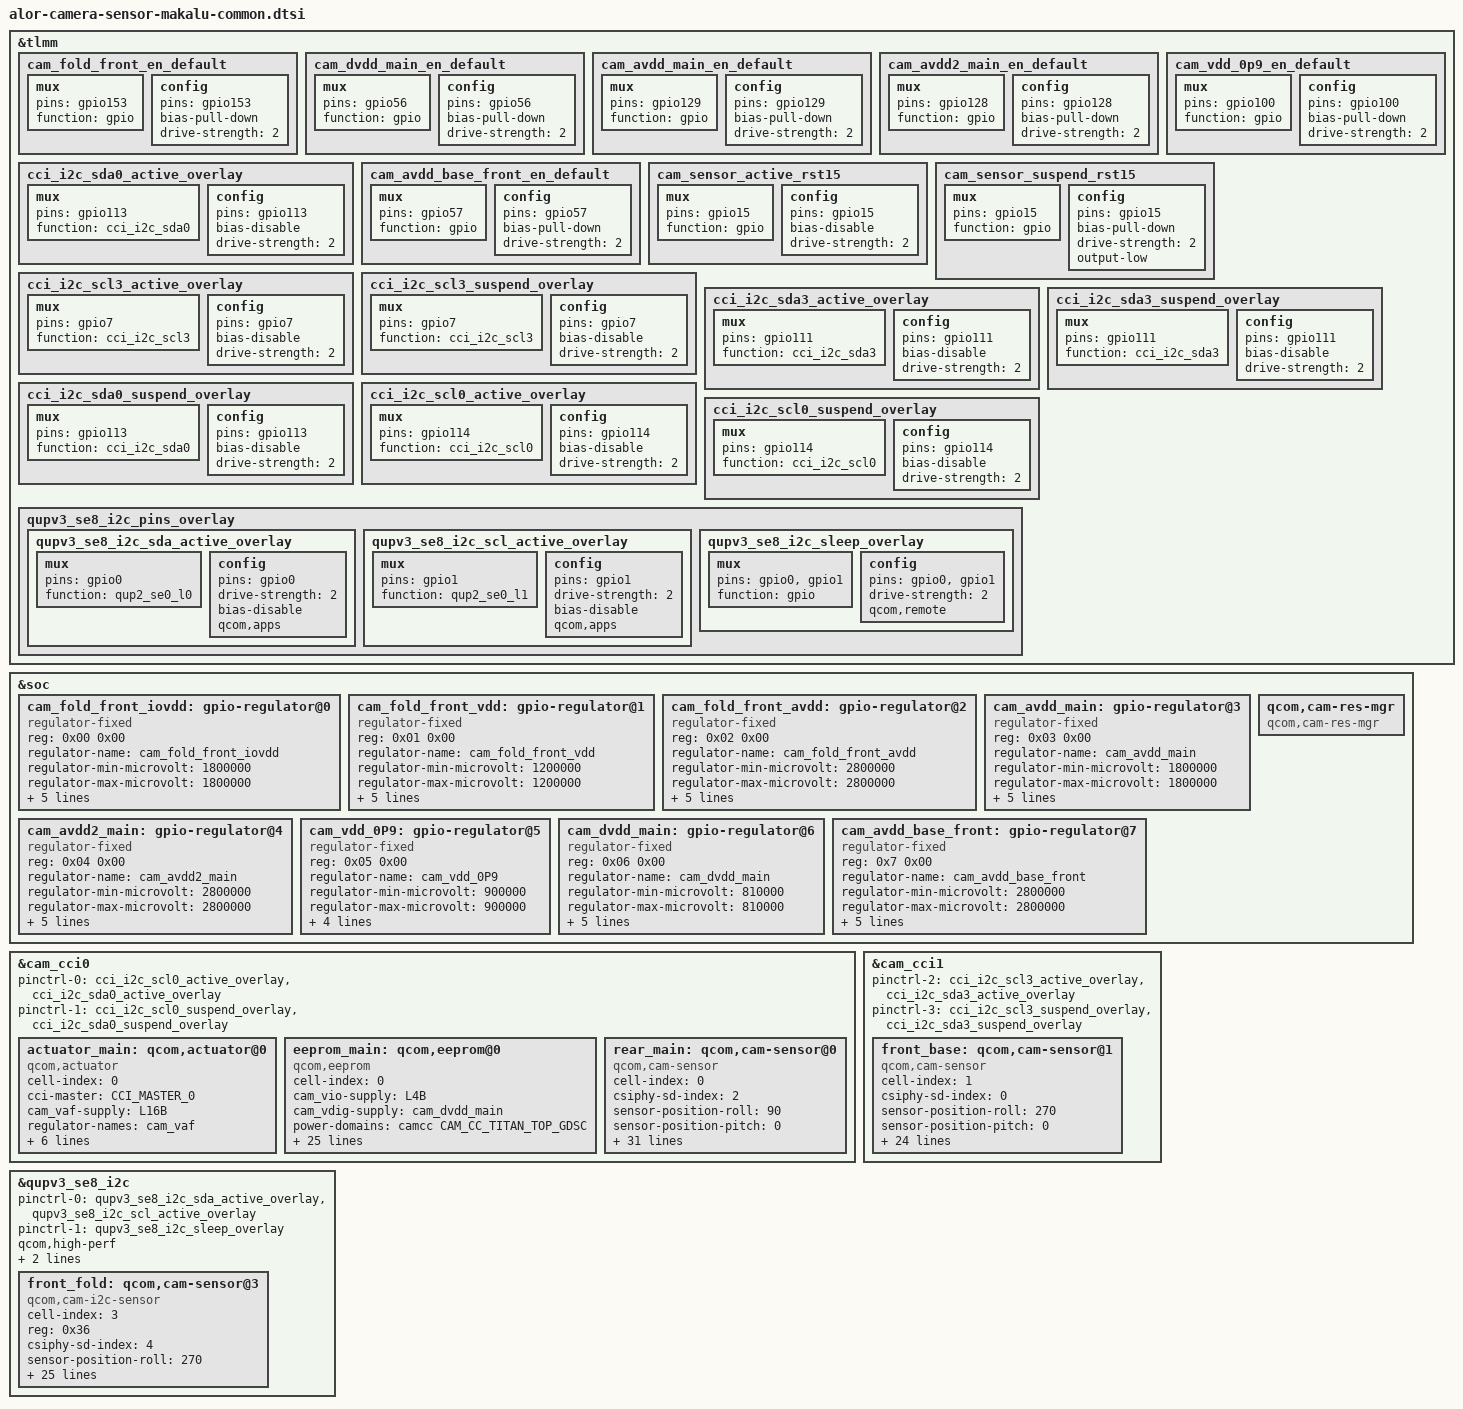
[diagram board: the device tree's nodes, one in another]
// SPDX-License-Identifier: BSD-3-Clause
/*
 * Copyright (c) 2024 Qualcomm Innovation Center, Inc. All rights reserved.
 */

#include <dt-bindings/msm-camera.h>

&tlmm {
	cam_fold_front_en_default: cam_fold_front_en_default {
		mux {
			pins = "gpio153";
			function = "gpio";
		};

		config {
			pins = "gpio153";
			bias-pull-down; /* PULL DOWN */
			drive-strength = <2>; /* 2 MA */
		};
	};

	cam_dvdd_main_en_default: cam_dvdd_main_en_default {
		mux {
			pins = "gpio56";
			function = "gpio";
		};

		config {
			pins = "gpio56";
			bias-pull-down; /* PULL DOWN */
			drive-strength = <2>; /* 2 MA */
		};
	};

	cam_avdd_main_en_default: cam_avdd_main_en_default {
		mux {
			pins = "gpio129";
			function = "gpio";
		};

		config {
			pins = "gpio129";
			bias-pull-down; /* PULL DOWN */
			drive-strength = <2>; /* 2 MA */
		};
	};

	cam_avdd2_main_en_default: cam_avdd2_main_en_default {
		mux {
			pins = "gpio128";
			function = "gpio";
		};

		config {
			pins = "gpio128";
			bias-pull-down; /* PULL DOWN */
			drive-strength = <2>; /* 2 MA */
		};
	};

	cam_vdd_0p9_en_default: cam_vdd_0p9_en_default {
		mux {
			pins = "gpio100";
			function = "gpio";
		};

		config {
			pins = "gpio100";
			bias-pull-down; /* PULL DOWN */
			drive-strength = <2>; /* 2 MA */
		};
	};

	cci_i2c_sda0_active_overlay: cci_i2c_sda0_active_overlay {
		/* SDA0 */
		mux {
			pins = "gpio113";
			function = "cci_i2c_sda0";
		};

		config {
			pins = "gpio113";
			bias-disable;
			drive-strength = <2>; /* 2 MA */
		};
	};

	cam_avdd_base_front_en_default: cam_avdd_base_front_en_default {
		mux {
			pins = "gpio57";
			function = "gpio";
		};

		config {
			pins = "gpio57";
			bias-pull-down; /* PULL DOWN */
			drive-strength = <2>; /* 2 MA */
		};
	};

	cam_sensor_active_rst15: cam_sensor_active_rst15 {
		mux {
			pins = "gpio15";
			function = "gpio";
		};

		config {
			pins = "gpio15";
			bias-disable; /* No PULL */
			drive-strength = <2>; /* 2 MA */
		};
	};

	cam_sensor_suspend_rst15: cam_sensor_suspend_rst15 {
		mux {
			pins = "gpio15";
			function = "gpio";
		};

		config {
			pins = "gpio15";
			bias-pull-down; /* PULL DOWN */
			drive-strength = <2>; /* 2 MA */
			output-low;
		};
	};

	cci_i2c_scl3_active_overlay: cci_i2c_scl3_active_overlay {
		/* SCL3 */
		mux {
			pins = "gpio7";
			function = "cci_i2c_scl3";
		};

		config {
			pins = "gpio7";
			bias-disable;
			drive-strength = <2>; /* 2 MA */
		};
	};

	cci_i2c_scl3_suspend_overlay: cci_i2c_scl3_suspend_overlay {
		/* SCL3 */
		mux {
			pins = "gpio7";
			function = "cci_i2c_scl3";
		};

		config {
			pins = "gpio7";
			bias-disable;
			drive-strength = <2>; /* 2 MA */
		};
	};

	cci_i2c_sda3_active_overlay: cci_i2c_sda3_active_overlay {
		/* SDA3 */
		mux {
			pins = "gpio111";
			function = "cci_i2c_sda3";
		};

		config {
			pins = "gpio111";
			bias-disable;
			drive-strength = <2>; /* 2 MA */
		};
	};

	cci_i2c_sda3_suspend_overlay: cci_i2c_sda3_suspend_overlay {
		/* SDA3 */
		mux {
			pins = "gpio111";
			function = "cci_i2c_sda3";
		};

		config {
			pins = "gpio111";
			bias-disable;
			drive-strength = <2>; /* 2 MA */
		};
	};

	cci_i2c_sda0_suspend_overlay: cci_i2c_sda0_suspend_overlay {
		/* SDA0 */
		mux {
			pins = "gpio113";
			function = "cci_i2c_sda0";
		};

		config {
			pins = "gpio113";
			bias-disable;
			drive-strength = <2>; /* 2 MA */
		};
	};

	cci_i2c_scl0_active_overlay: cci_i2c_scl0_active_overlay {
		/* SCL0 */
		mux {
			pins = "gpio114";
			function = "cci_i2c_scl0";
		};

		config {
			pins = "gpio114";
			bias-disable;
			drive-strength = <2>; /* 2 MA */
		};
	};

	cci_i2c_scl0_suspend_overlay: cci_i2c_scl0_suspend_overlay {
		/* SCL0 */
		mux {
			pins = "gpio114";
			function = "cci_i2c_scl0";
		};

		config {
			pins = "gpio114";
			bias-disable;
			drive-strength = <2>; /* 2 MA */
		};
	};

	qupv3_se8_i2c_pins_overlay: qupv3_se8_i2c_pins_overlay {
		qupv3_se8_i2c_sda_active_overlay: qupv3_se8_i2c_sda_active_overlay {
			mux {
				pins = "gpio0";
				function = "qup2_se0_l0";
			};

			config {
				pins = "gpio0";
				drive-strength = <2>;
				bias-disable;
				qcom,apps;
			};
		};

		qupv3_se8_i2c_scl_active_overlay: qupv3_se8_i2c_scl_active_overlay {
			mux {
				pins = "gpio1";
				function = "qup2_se0_l1";
			};

			config {
				pins = "gpio1";
				drive-strength = <2>;
				bias-disable;
				qcom,apps;
			};
		};

		qupv3_se8_i2c_sleep_overlay: qupv3_se8_i2c_sleep_overlay {
			mux {
				pins = "gpio0", "gpio1";
				function = "gpio";
			};

			config {
				pins = "gpio0", "gpio1";
				drive-strength = <2>;
				qcom,remote;
			};
		};
	};
};

&soc {
	cam_fold_front_iovdd: gpio-regulator@0 {
		compatible = "regulator-fixed";
		reg = <0x00 0x00>;
		regulator-name = "cam_fold_front_iovdd";
		regulator-min-microvolt = <1800000>;
		regulator-max-microvolt = <1800000>;
		regulator-enable-ramp-delay = <233>;
		enable-active-high;
		gpio = <&tlmm 153 0>;
		pinctrl-names = "default";
		pinctrl-0 = <&cam_fold_front_en_default>;
		vin-supply = <&S4D>;
	};

	cam_fold_front_vdd: gpio-regulator@1 {
		compatible = "regulator-fixed";
		reg = <0x01 0x00>;
		regulator-name = "cam_fold_front_vdd";
		regulator-min-microvolt = <1200000>;
		regulator-max-microvolt = <1200000>;
		regulator-enable-ramp-delay = <233>;
		enable-active-high;
		gpio = <&tlmm 153 0>;
		pinctrl-names = "default";
		pinctrl-0 = <&cam_fold_front_en_default>;
		vin-supply = <&S4F>;
	};

	cam_fold_front_avdd: gpio-regulator@2 {
		compatible = "regulator-fixed";
		reg = <0x02 0x00>;
		regulator-name = "cam_fold_front_avdd";
		regulator-min-microvolt = <2800000>;
		regulator-max-microvolt = <2800000>;
		regulator-enable-ramp-delay = <233>;
		enable-active-high;
		gpio = <&tlmm 153 0>;
		pinctrl-names = "default";
		pinctrl-0 = <&cam_fold_front_en_default>;
		vin-supply = <&BOB1>;
	};

	cam_avdd_main: gpio-regulator@3 {
		compatible = "regulator-fixed";
		reg = <0x03 0x00>;
		regulator-name = "cam_avdd_main";
		regulator-min-microvolt = <1800000>;
		regulator-max-microvolt = <1800000>;
		regulator-enable-ramp-delay = <233>;
		enable-active-high;
		gpio = <&tlmm 129 0>;
		pinctrl-names = "default";
		pinctrl-0 = <&cam_avdd_main_en_default>;
		vin-supply = <&S4D>;
	};

	cam_avdd2_main: gpio-regulator@4 {
		compatible = "regulator-fixed";
		reg = <0x04 0x00>;
		regulator-name = "cam_avdd2_main";
		regulator-min-microvolt = <2800000>;
		regulator-max-microvolt = <2800000>;
		regulator-enable-ramp-delay = <233>;
		enable-active-high;
		gpio = <&tlmm 128 0>;
		pinctrl-names = "default";
		pinctrl-0 = <&cam_avdd2_main_en_default>;
		vin-supply = <&BOB1>;
	};

	cam_vdd_0P9: gpio-regulator@5 {
		compatible = "regulator-fixed";
		reg = <0x05 0x00>;
		regulator-name = "cam_vdd_0P9";
		regulator-min-microvolt = <900000>;
		regulator-max-microvolt = <900000>;
		regulator-enable-ramp-delay = <233>;
		enable-active-high;
		gpio = <&tlmm 100 0>;
		pinctrl-names = "default";
		pinctrl-0 = <&cam_vdd_0p9_en_default>;
		//vin-supply = <&BOB1>; //B_PLUS
	};

	cam_dvdd_main: gpio-regulator@6 {
		compatible = "regulator-fixed";
		reg = <0x06 0x00>;
		regulator-name = "cam_dvdd_main";
		regulator-min-microvolt = <810000>;
		regulator-max-microvolt = <810000>;
		regulator-enable-ramp-delay = <233>;
		enable-active-high;
		gpio = <&tlmm 56 0>;
		pinctrl-names = "default";
		pinctrl-0 = <&cam_dvdd_main_en_default>;
		vin-supply = <&cam_vdd_0P9>;
	};

	cam_avdd_base_front: gpio-regulator@7 {
		compatible = "regulator-fixed";
		reg = <0x7 0x00>;
		regulator-name = "cam_avdd_base_front";
		regulator-min-microvolt = <2800000>;
		regulator-max-microvolt = <2800000>;
		regulator-enable-ramp-delay = <233>;
		enable-active-high;
		gpio = <&tlmm 57 0>;
		pinctrl-names = "default";
		pinctrl-0 = <&cam_avdd_base_front_en_default>;
		vin-supply = <&BOB1>;
	};

	qcom,cam-res-mgr {
		compatible = "qcom,cam-res-mgr";
		status = "ok";
	};
};

&cam_cci0 {
	pinctrl-0 = <&cci_i2c_scl0_active_overlay &cci_i2c_sda0_active_overlay>;
	pinctrl-1 = <&cci_i2c_scl0_suspend_overlay &cci_i2c_sda0_suspend_overlay>;

	actuator_main: qcom,actuator@0 {
		cell-index = <0>;
		compatible = "qcom,actuator";
		cci-master = <CCI_MASTER_0>;
		cam_vaf-supply = <&L16B>;
		regulator-names = "cam_vaf";
		rgltr-cntrl-support;
		rgltr-min-voltage = <3000000>;
		rgltr-max-voltage = <3000000>;
		rgltr-load-current = <119000>;
		af-drift-support;
		status = "ok";
		multi-user-support;
	};

	eeprom_main: qcom,eeprom@0 {
		cell-index = <0>;
		compatible = "qcom,eeprom";
		cam_vio-supply = <&L4B>;
		cam_vdig-supply = <&cam_dvdd_main>;
		power-domains = <&camcc CAM_CC_TITAN_TOP_GDSC>;
		cam_vana-supply = <&cam_avdd2_main>;
		cam_v_custom1-supply = <&cam_avdd_main>;
		regulator-names = "cam_vio", "cam_vdig","cam_vana", "cam_v_custom1";
		rgltr-cntrl-support;
		rgltr-min-voltage = <1800000 810000 2800000 1800000>;
		rgltr-max-voltage = <1800000 810000 2800000 1800000>;
		rgltr-load-current = <3500 913200 91430 63100>;
		gpio-no-mux = <0>;
		pinctrl-names = "cam_default", "cam_suspend";
		pinctrl-0 = <&cam_sensor_mclk2_active &cam_sensor_active_rst2>;
		pinctrl-1 = <&cam_sensor_mclk2_suspend &cam_sensor_suspend_rst2>;
		gpios = <&tlmm 91 0>,<&tlmm 90 0>;
		gpio-reset = <1>;
		gpio-req-tbl-num = <0 1>;
		gpio-req-tbl-flags = <1 0>;
		gpio-req-tbl-label = "CAMIF_MCLK2","CAM_RESET2";
		cci-master = <CCI_MASTER_0>;
		clocks = <&cambistmclkcc CAM_BIST_MCLK_CC_MCLK2_CLK>;
		clock-names = "cam_clk";
		clock-cntl-level = "nominal";
		clock-rates = <19200000>;
		status = "ok";
	};

	rear_main: qcom,cam-sensor@0 {
		cell-index = <0>;
		compatible = "qcom,cam-sensor";
		csiphy-sd-index = <2>;
		sensor-position-roll  = <90>;
		sensor-position-pitch = <0>;
		sensor-position-yaw   = <180>;
		eeprom-src    = <&eeprom_main>;
		//ois-src       = <&ois_main>;
		actuator-src  = <&actuator_main>;
		//led-flash-src = <&led_flash_main>;
		cam_vio-supply       = <&L4B>;
		cam_vdig-supply      = <&cam_dvdd_main>;
		power-domains        = <&camcc CAM_CC_TITAN_TOP_GDSC>;
		cam_vana-supply      = <&cam_avdd2_main>;
		cam_v_custom1-supply = <&cam_avdd_main>;
		regulator-names    = "cam_vio","cam_vdig","cam_vana","cam_v_custom1";
		rgltr-cntrl-support;
		rgltr-min-voltage  = <1800000 810000 2800000 1800000>;
		rgltr-max-voltage  = <1800000 810000 2800000 1800000>;
		rgltr-load-current = <3500    913200   91430   63100>;
		gpio-no-mux = <0>;
		pinctrl-names = "cam_default","cam_suspend";
		pinctrl-0     = <&cam_sensor_mclk2_active  &cam_sensor_active_rst2>;
		pinctrl-1     = <&cam_sensor_mclk2_suspend &cam_sensor_suspend_rst2>;
		gpios              = <&tlmm 91 0>,<&tlmm 90 0>;
		gpio-reset         = <1>;
		gpio-req-tbl-num   = <0 1>;
		gpio-req-tbl-flags = <1 0>;
		gpio-req-tbl-label = "CAMIF_MCLK2","CAM_RESET2";
		cci-master = <CCI_MASTER_0>;
		clocks           = <&cambistmclkcc CAM_BIST_MCLK_CC_MCLK2_CLK>;
		clock-names      = "cam_clk";
		clock-cntl-level = "nominal";
		clock-rates      = <19200000>;
		status = "ok";
	};
};

&cam_cci1 {
	pinctrl-2 = <&cci_i2c_scl3_active_overlay &cci_i2c_sda3_active_overlay>;
	pinctrl-3 = <&cci_i2c_scl3_suspend_overlay &cci_i2c_sda3_suspend_overlay>;

	front_base: qcom,cam-sensor@1 {
		cell-index = <1>;
		compatible = "qcom,cam-sensor";
		csiphy-sd-index = <0>;
		sensor-position-roll  = <270>;
		sensor-position-pitch = <0>;
		sensor-position-yaw   = <0>;

		//eeprom-src   = <&eeprom_base>;
		cam_vio-supply  = <&L4B>;
		//cam_vdig-supply = <&cam2_ldo2>;
		power-domains   = <&camcc CAM_CC_TITAN_TOP_GDSC>;
		cam_vana-supply = <&cam_avdd_base_front>;
		regulator-names = "cam_vio","cam_vdig","cam_vana";
		rgltr-cntrl-support;
		rgltr-min-voltage = <1800000 1200000 2800000>;
		rgltr-max-voltage = <1800000 1200000 2800000>;
		rgltr-load-current = <3500    913200   91430>;

		gpio-no-mux = <0>;
		pinctrl-names = "cam_default", "cam_suspend";
		pinctrl-0 = <&cam_sensor_mclk5_active  &cam_sensor_active_rst15>;
		pinctrl-1 = <&cam_sensor_mclk5_suspend &cam_sensor_suspend_rst15>;
		gpios              = <&tlmm 94 0>,
                                     <&tlmm 15 0>;
		gpio-reset         = <1>;
		gpio-req-tbl-num   = <0 1>;
		gpio-req-tbl-flags = <1 0>;
		gpio-req-tbl-label = "CAMIF_MCLK5",
                                     "CAM_RESET15";
		cci-master = <CCI_MASTER_1>;
		clocks           = <&cambistmclkcc CAM_BIST_MCLK_CC_MCLK5_CLK>;
		clock-names      = "cam_clk";
		clock-cntl-level = "nominal";
		clock-rates      = <19200000>;
		status = "ok";
	};
};

&qupv3_se8_i2c {
	pinctrl-0 = <&qupv3_se8_i2c_sda_active_overlay>, <&qupv3_se8_i2c_scl_active_overlay>;
	pinctrl-1 = <&qupv3_se8_i2c_sleep_overlay>;

	status = "ok";
	qcom,high-perf;
	qcom,clk-freq-out = <1000000>;
	qcom,pm-ctrl-client;

	front_fold: qcom,cam-sensor@3 {
		cell-index = <3>;
		reg = <0x36>;
		compatible = "qcom,cam-i2c-sensor";
		csiphy-sd-index = <4>;
		sensor-position-roll = <270>;
		sensor-position-pitch = <0>;
		sensor-position-yaw = <0>;
		//eeprom-src   = <&eeprom_fold>;
		cam_vio-supply = <&cam_fold_front_iovdd>;
		cam_vdig-supply = <&cam_fold_front_vdd>;
		power-domains   = <&camcc CAM_CC_TITAN_TOP_GDSC>;
		cam_vana-supply = <&cam_fold_front_avdd>;
		regulator-names = "cam_vio", "cam_vdig", "cam_vana";
		rgltr-cntrl-support;
		rgltr-min-voltage = <1800000 1200000 2800000>;
		rgltr-max-voltage = <1800000 1200000 2800000>;
		rgltr-load-current = <3500   913200  91430>;
		gpio-no-mux = <0>;
		pinctrl-names = "cam_default", "cam_suspend";
		pinctrl-0 = <&cam_sensor_mclk4_active &cam_sensor_active_rst4>;
		pinctrl-1 = <&cam_sensor_mclk4_suspend &cam_sensor_suspend_rst4>;
		gpios = <&tlmm 93 0>,
			<&tlmm 3 0>;
		gpio-reset = <1>;
		gpio-req-tbl-num = <0 1>;
		gpio-req-tbl-flags = <1 0>;
		gpio-req-tbl-label = "CAMIF_MCLK4","CAM_RESET4";
		clocks = <&cambistmclkcc CAM_BIST_MCLK_CC_MCLK4_CLK>;
		clock-names = "cam_clk";
		clock-cntl-level = "nominal";
		clock-rates = <19200000>;
		status = "ok";
	};
};
